AUTOSAR XML (schema 314)
package /ComponentType
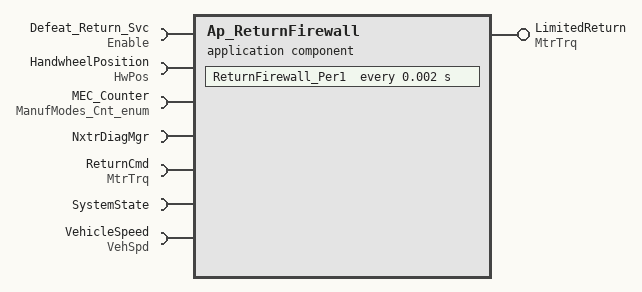
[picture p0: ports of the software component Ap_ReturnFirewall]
  application software component type Ap_ReturnFirewall
    provide port LimitedReturn: unqueued-sender-com-spec{data-element=MtrNm_f32, can-invalidate=false, init-value=D_ZERO_ULS_F32}, provided-interface=MtrTrq
    7 x require port:
      Defeat_Return_Svc: unqueued-receiver-com-spec{data-element=Cnt_lgc, init-value=D_FALSE_CNT_LGC}, required-interface=Enable
      HandwheelPosition: unqueued-receiver-com-spec{data-element=HwDeg_f32, init-value=D_ZERO_ULS_F32}, required-interface=HwPos
      MEC_Counter: unqueued-receiver-com-spec{data-element=Cnt_enum, init-value=D_MANUFMODEINIT_CNT_ENUM}, required-interface=ManufModes_Cnt_enum
      NxtrDiagMgr: required-com-specs=[GetNTCActive, GetNTCFailed, GetNTCStatus, SetNTCStatus], required-interface=NxtrDiagMgr
      ReturnCmd: unqueued-receiver-com-spec{data-element=MtrNm_f32, init-value=D_ZERO_ULS_F32}, required-interface=MtrTrq
      SystemState: required-interface=SystemState
      VehicleSpeed: unqueued-receiver-com-spec{data-element=Kph_f32, init-value=D_ZERO_ULS_F32}, required-interface=VehSpd
  internal behavior Ap_ReturnFirewall_InternalBehavior: component=Ap_ReturnFirewall
    timing event TMT_ReturnFirewall_Per1: mode-dependency=dependent-on-mode=[SystemState.Mode.OFF, SystemState.Mode.WARMINIT], start-on-event=ReturnFirewall_Per1, period=0.002
    port-api-options:
      enable-take-address=false, indirect-api=false, port=Defeat_Return_Svc
      enable-take-address=false, indirect-api=false, port=HandwheelPosition
      enable-take-address=false, indirect-api=false, port=LimitedReturn
      enable-take-address=false, indirect-api=false, port=MEC_Counter
      enable-take-address=false, indirect-api=false, port=NxtrDiagMgr
      enable-take-address=false, indirect-api=false, port=ReturnCmd
      enable-take-address=false, indirect-api=false, port=SystemState
      enable-take-address=false, indirect-api=false, port=VehicleSpeed
    runnable ReturnFirewall_Per1
      5 x data read access:
        READ_Defeat_Return_Svc_Cnt_lgc: data-element=Defeat_Return_Svc.Cnt_lgc
        READ_HandwheelPosition_HwDeg_f32: data-element=HandwheelPosition.HwDeg_f32
        READ_MEC_Counter_Cnt_enum: data-element=MEC_Counter.Cnt_enum
        READ_ReturnCmd_MtrNm_f32: data-element=ReturnCmd.MtrNm_f32
        READ_VehicleSpeed_Kph_f32: data-element=VehicleSpeed.Kph_f32
      data write access WRITE_LimitedReturn_MtrNm_f32: data-element=LimitedReturn.MtrNm_f32
      sync call SC_NxtrDiagMgr_SetNTCStatus: operation=NxtrDiagMgr.SetNTCStatus, timeout=0
  swc implementation Ap_ReturnFirewall_Implementation: behavior=Ap_ReturnFirewall_InternalBehavior
    code-descriptors:
      code Code: type=SRC
